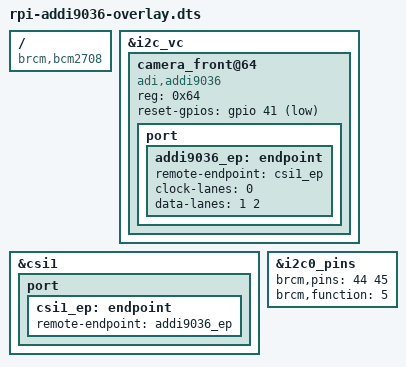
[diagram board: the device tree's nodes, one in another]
// Definitions for ADDI9036 camera module
/dts-v1/;
/plugin/;

/{
	compatible = "brcm,bcm2708";

	fragment@0 {
		target = <&i2c_vc>;
		__overlay__ {
			#address-cells = <1>;
			#size-cells = <0>;
			status = "okay";

			camera_front@64 {
				compatible = "adi,addi9036";
				reg = <0x64>;

				reset-gpios = <&gpio 41 1>;

				port {
					addi9036_ep: endpoint {
						remote-endpoint = <&csi1_ep>;
						clock-lanes = <0>;
						data-lanes = <1 2>;
					};
				};
			};
		};
	};

	fragment@1 {
		target = <&csi1>;
		__overlay__ {
			status = "okay";

			port {
				csi1_ep: endpoint {
					remote-endpoint = <&addi9036_ep>;
				};
			};
		};
	};

	fragment@2 {
		target = <&i2c0_pins>;
		__overlay__ {
			brcm,pins = <44 45>;
			brcm,function = <5>; /* alt1 */
		};
	};

	fragment@3 {
		target = <&i2c_vc>;
		__overlay__ {
			status = "okay";
		};
	};

	fragment@4 {
		target = <&i2c1>;
		__dormant__ {
			pinctrl-0 = <&i2c1_pins>;
			status = "okay";
		};
	};

/* Fragment valid only for ADI ToF REV B */
	fragment@5 {
		target = <&i2c1>;
		__dormant__ {
			#address-cells = <1>;
			#size-cells = <0>;

			eeprom_i2c1: eeprom@56 {
				compatible = "atmel,24c1024";
				reg = <0x56>;
				pagesize = <32>;
			};
		};
	};

/* Fragment valid only for ADI ToF REV C */
	fragment@6 {
		target = <&i2c_vc>;
		__dormant__ {
			#address-cells = <1>;
			#size-cells = <0>;

			eeprom_i2c_vc: eeprom@56 {
				compatible = "atmel,24c1024";
				reg = <0x56>;
				pagesize = <32>;
			};
		};
	};

	fragment@7 {
		target = <&i2c1_pins>;
		__dormant__ {
			brcm,pins = <2 3>;
			brcm,function = <4>; /* alt 0 */
		};
	};

/* Fragment valid only for Chicony */
	fragment@8 {
		target = <&i2c_vc>;
		__dormant__ {
			#address-cells = <1>;
			#size-cells = <0>;

			tmp102_i2c_vc: temp@48 {
				compatible = "ti,tmp102";
				reg = <0x48>;
			};
		};
	};

/* Fragment valid only for Foxconn */
	fragment@9 {
		target = <&i2c_vc>;
		__dormant__ {
			#address-cells = <1>;
			#size-cells = <0>;

			tmp103_i2c_vc: temp@73 {
				compatible = "ti,tmp103";
				reg = <0x73>;
			};
		};
	};

	__overrides__ {
		revb = <0>,"+4+5-6+7-8-9";
		revc = <0>,"-4-5+6-7-8-9";
		chicony = <0>,"-4-5+6-7+8-9";
		foxconn = <0>,"-4-5+6-7-8+9";
	};
};
